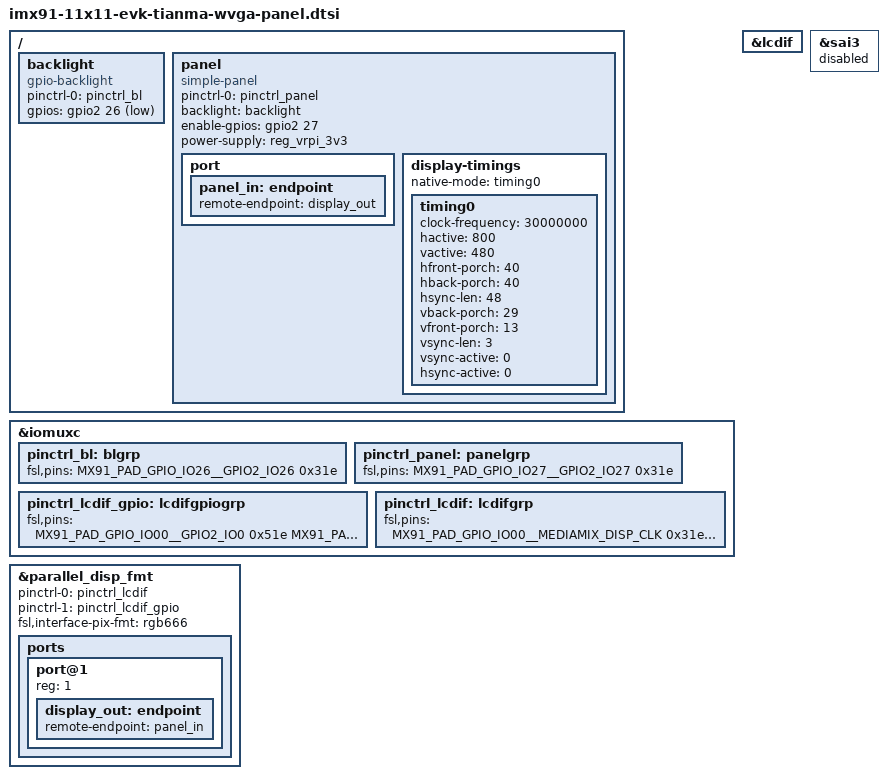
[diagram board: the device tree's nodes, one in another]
// SPDX-License-Identifier: (GPL-2.0+ OR MIT)
/*
 * Copyright 2024 NXP
 */


/ {
	backlight: backlight {
		compatible = "gpio-backlight";
		pinctrl-names = "default";
		pinctrl-0 = <&pinctrl_bl>;
		gpios = <&gpio2 26 GPIO_ACTIVE_LOW>;
	};

	panel {
		compatible = "simple-panel";
		pinctrl-names = "default";
		pinctrl-0 = <&pinctrl_panel>;
		backlight = <&backlight>;
		enable-gpios = <&gpio2 27 GPIO_ACTIVE_HIGH>;
		power-supply = <&reg_vrpi_3v3>;

		port {
			panel_in: endpoint {
				remote-endpoint = <&display_out>;
			};
		};

		display-timings {
			native-mode = <&timing0>;
			timing0: timing0 {
				clock-frequency = <30000000>;
				hactive = <800>;
				vactive = <480>;
				hfront-porch = <40>;
				hback-porch = <40>;
				hsync-len = <48>;
				vback-porch = <29>;
				vfront-porch = <13>;
				vsync-len = <3>;

				vsync-active = <0>;
				hsync-active = <0>;
			};
		};
	};
};

&iomuxc {
	pinctrl_bl: blgrp {
		fsl,pins = <
			MX91_PAD_GPIO_IO26__GPIO2_IO26    0x31e
		>;
	};

	pinctrl_panel: panelgrp {
		fsl,pins = <
			MX91_PAD_GPIO_IO27__GPIO2_IO27    0x31e
		>;
	};
};

&lcdif {
	status = "okay";
	/*assigned-clock-rates = <150000000>, <30000000>, <400000000>, <133333333>;*/
};

&parallel_disp_fmt {
	pinctrl-names = "default", "gpio";
	pinctrl-0 = <&pinctrl_lcdif>;
	pinctrl-1 = <&pinctrl_lcdif_gpio>;
	fsl,interface-pix-fmt = "rgb666";
	status = "okay";

	ports {
		port@1 {
			reg = <1>;

			display_out: endpoint {
				remote-endpoint = <&panel_in>;
			};
		};
	};
};

/* pin conflicts */
&sai3 {
	status = "disabled";
};

&iomuxc {
	pinctrl_lcdif_gpio: lcdifgpiogrp {
		fsl,pins = <
			MX91_PAD_GPIO_IO00__GPIO2_IO0			0x51e
			MX91_PAD_GPIO_IO01__GPIO2_IO1			0x51e
			MX91_PAD_GPIO_IO02__GPIO2_IO2			0x51e
			MX91_PAD_GPIO_IO03__GPIO2_IO3			0x51e
		>;
	};

	pinctrl_lcdif: lcdifgrp {
		fsl,pins = <
			MX91_PAD_GPIO_IO00__MEDIAMIX_DISP_CLK		0x31e
			MX91_PAD_GPIO_IO01__MEDIAMIX_DISP_DE		0x31e
			MX91_PAD_GPIO_IO02__MEDIAMIX_DISP_VSYNC		0x31e
			MX91_PAD_GPIO_IO03__MEDIAMIX_DISP_HSYNC		0x31e
			MX91_PAD_GPIO_IO04__MEDIAMIX_DISP_DATA0		0x31e
			MX91_PAD_GPIO_IO05__MEDIAMIX_DISP_DATA1		0x31e
			MX91_PAD_GPIO_IO06__MEDIAMIX_DISP_DATA2		0x31e
			MX91_PAD_GPIO_IO07__MEDIAMIX_DISP_DATA3		0x31e
			MX91_PAD_GPIO_IO08__MEDIAMIX_DISP_DATA4		0x31e
			MX91_PAD_GPIO_IO09__MEDIAMIX_DISP_DATA5		0x31e
			MX91_PAD_GPIO_IO10__MEDIAMIX_DISP_DATA6		0x31e
			MX91_PAD_GPIO_IO11__MEDIAMIX_DISP_DATA7		0x31e
			MX91_PAD_GPIO_IO12__MEDIAMIX_DISP_DATA8		0x31e
			MX91_PAD_GPIO_IO13__MEDIAMIX_DISP_DATA9		0x31e
			MX91_PAD_GPIO_IO14__MEDIAMIX_DISP_DATA10	0x31e
			MX91_PAD_GPIO_IO15__MEDIAMIX_DISP_DATA11	0x31e
			MX91_PAD_GPIO_IO16__MEDIAMIX_DISP_DATA12	0x31e
			MX91_PAD_GPIO_IO17__MEDIAMIX_DISP_DATA13	0x31e
			MX91_PAD_GPIO_IO18__MEDIAMIX_DISP_DATA14	0x31e
			MX91_PAD_GPIO_IO19__MEDIAMIX_DISP_DATA15	0x31e
			MX91_PAD_GPIO_IO20__MEDIAMIX_DISP_DATA16	0x31e
			MX91_PAD_GPIO_IO21__MEDIAMIX_DISP_DATA17	0x31e
			MX91_PAD_GPIO_IO27__GPIO2_IO27			0x31e
		>;
	};
};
